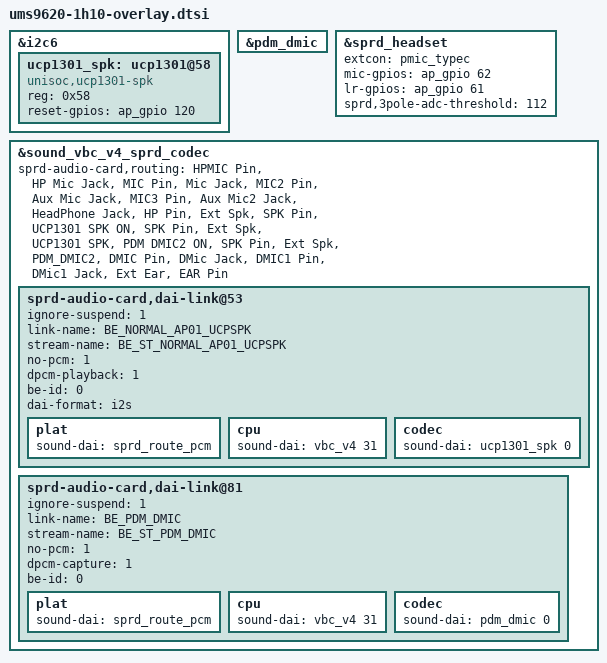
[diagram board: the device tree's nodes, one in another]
&i2c6 {
	#address-cells = <1>;
	#size-cells = <0>;

	status = "okay";
	ucp1301_spk: ucp1301@58 {
		compatible = "unisoc,ucp1301-spk";
		reg = <0x58>;
		reset-gpios = <&ap_gpio 120 GPIO_ACTIVE_HIGH>;
		#sound-dai-cells = <1>;
	};
};

&pdm_dmic {
	status = "okay";
};

&sprd_headset {
	status = "okay";
	extcon = <&pmic_typec>;
	mic-gpios = <&ap_gpio 62 GPIO_ACTIVE_HIGH>;
	lr-gpios = <&ap_gpio 61 GPIO_ACTIVE_HIGH>;
	sprd,3pole-adc-threshold = <112>;
};

&sound_vbc_v4_sprd_codec {
	status = "okay";
	sprd-audio-card,routing =
		"HPMIC Pin", "HP Mic Jack",
		"MIC Pin", "Mic Jack",
		"MIC2 Pin", "Aux Mic Jack",
		"MIC3 Pin", "Aux Mic2 Jack",
		"HeadPhone Jack", "HP Pin",
		"Ext Spk", "SPK Pin",
		"UCP1301 SPK ON", "SPK Pin",
		"Ext Spk", "UCP1301 SPK",
		"PDM DMIC2 ON", "SPK Pin",
		"Ext Spk", "PDM_DMIC2",
		"DMIC Pin", "DMic Jack",
		"DMIC1 Pin", "DMic1 Jack",
		"Ext Ear", "EAR Pin";

	/* 35: ucp1301 normal ap01 */
	sprd-audio-card,dai-link@53 {
		ignore-suspend = <1>;
		link-name = "BE_NORMAL_AP01_UCPSPK";
		stream-name = "BE_ST_NORMAL_AP01_UCPSPK";
		no-pcm = <1>;
		dpcm-playback = <1>;
		be-id = <0>;
		dai-format = "i2s";
		plat {
			sound-dai = <&sprd_route_pcm>;
		};
		cpu {
			sound-dai = <&vbc_v4 31>;
		};
		codec {
			sound-dai = <&ucp1301_spk 0>;
		};
	};

	/*
	 * node 54 and node 55 (index 36 and 37) are reserved for
	 * "ucp1301-spk2" and "ucp1301-rcv"
	 * nodes from 56 to 67 (index from 38 to 49) are used by HIFI
	 */
	/* 63: pdm dmic */
	sprd-audio-card,dai-link@81 {
		ignore-suspend = <1>;
		link-name = "BE_PDM_DMIC";
		stream-name = "BE_ST_PDM_DMIC";
		no-pcm = <1>;
		dpcm-capture = <1>;
		be-id = <0>;
		//dai-format = "i2s";
		plat {
			sound-dai = <&sprd_route_pcm>;
		};
		cpu {
			sound-dai = <&vbc_v4 31>;
		};
		codec {
			sound-dai = <&pdm_dmic 0>;
		};
	};
};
